CM_ "IMPORT _honda_fit_2018.dbc";
CM_ "IMPORT _honda_2017.dbc";
CM_ "IMPORT _comma.dbc";

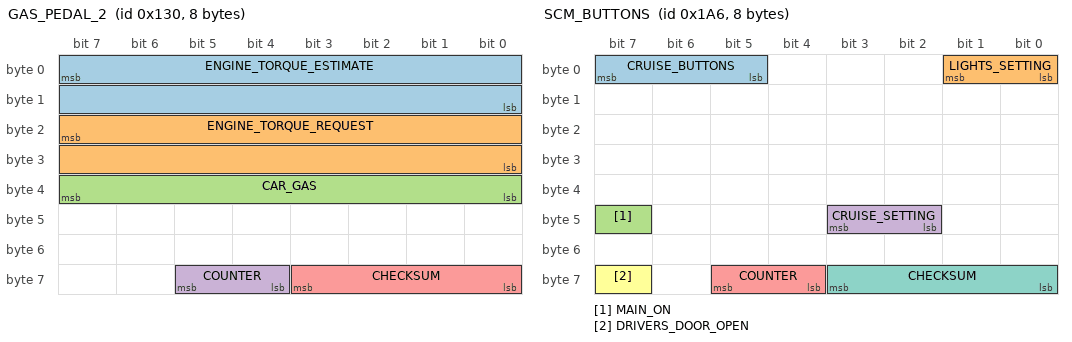
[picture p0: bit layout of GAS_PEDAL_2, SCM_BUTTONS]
BO_ 304 GAS_PEDAL_2: 8 PCM
 SG_ ENGINE_TORQUE_ESTIMATE : 7|16@0- (1,0) [-1000|1000] "Nm" EON
 SG_ ENGINE_TORQUE_REQUEST : 23|16@0- (1,0) [-1000|1000] "Nm" EON
 SG_ CAR_GAS : 39|8@0+ (1,0) [0|255] "" EON
 SG_ COUNTER : 61|2@0+ (1,0) [0|3] "" EON
 SG_ CHECKSUM : 59|4@0+ (1,0) [0|3] "" EON

BO_ 422 SCM_BUTTONS: 8 SCM
 SG_ CRUISE_BUTTONS : 7|3@0+ (1,0) [0|7] "" EON
 SG_ LIGHTS_SETTING : 1|2@0+ (1,0) [0|3] "" EON
 SG_ MAIN_ON : 47|1@0+ (1,0) [0|1] "" EON
 SG_ CRUISE_SETTING : 43|2@0+ (1,0) [0|3] "" EON
 SG_ COUNTER : 61|2@0+ (1,0) [0|3] "" EON
 SG_ DRIVERS_DOOR_OPEN : 63|1@0+ (1,0) [0|1] "" EON
 SG_ CHECKSUM : 59|4@0+ (1,0) [0|3] "" EON
